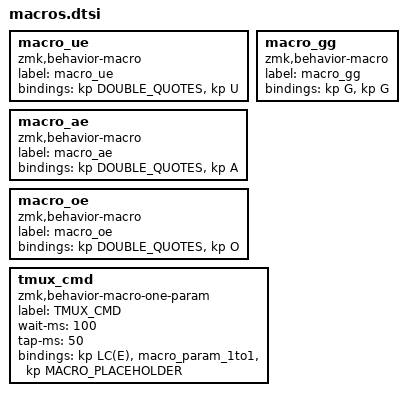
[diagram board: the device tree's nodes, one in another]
macro_ue: macro_ue{
compatible = "zmk,behavior-macro";
label = "macro_ue";
#binding-cells = <0>;
bindings = <&kp DOUBLE_QUOTES>, <&kp U>;
};
macro_ae: macro_ae{
compatible = "zmk,behavior-macro";
label = "macro_ae";
#binding-cells = <0>;
bindings = <&kp DOUBLE_QUOTES>, <&kp A>;
};
macro_oe: macro_oe{
compatible = "zmk,behavior-macro";
label = "macro_oe";
#binding-cells = <0>;
bindings = <&kp DOUBLE_QUOTES>, <&kp O>;
};
macro_gg: macro_gg{
compatible = "zmk,behavior-macro";
label = "macro_gg";
#binding-cells = <0>;
bindings = <&kp G>, <&kp G>;
};
tmux_cmd: tmux_cmd {
compatible = "zmk,behavior-macro-one-param";
label = "TMUX_CMD";
#binding-cells = <1>;
wait-ms = <100>;
tap-ms = <50>;
bindings
    = <&kp LC(E)>
    , <&macro_param_1to1>
    , <&kp MACRO_PLACEHOLDER>
    ;
};
